# PRU_ICSSG1_PR1_MII_RT_PR1_SGMII0_CFG_SGMII0_local register map
Vendor: Texas Instruments
Peripheral module from a debugger description file (folder J7ES).
Registers are 32-bit, read-write, reset 0x0 unless marked. A register's access mark holds for its fields unless they carry their own. Offsets are as the file gives them; lines under a group give offsets from that group; [hi:lo] are bit positions; {n}, {i} and the like mark numbered series; 'fields as' and 'values as' point back to an identical list; <NAME> marks a mode.

## PRU_ICSSG1_PR1_MII_RT_PR1_SGMII0_CFG_SGMII0
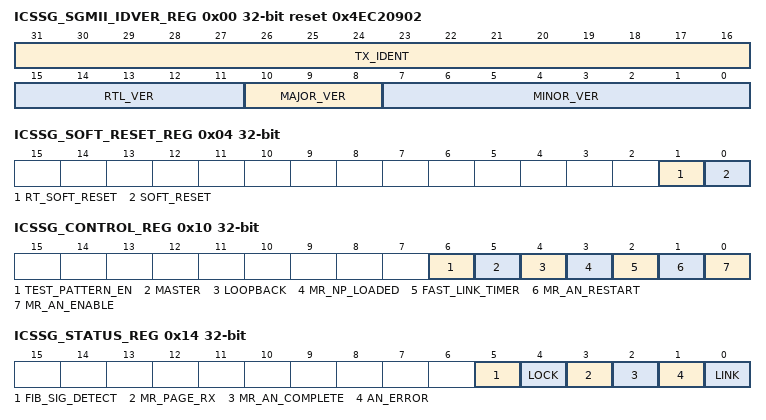
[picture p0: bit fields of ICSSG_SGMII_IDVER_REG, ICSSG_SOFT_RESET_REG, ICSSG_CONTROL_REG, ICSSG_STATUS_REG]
0x00 ICSSG_SGMII_IDVER_REG ro reset 0x4EC20902 — idver_reg
  [31:16] TX_IDENT
  [15:11] RTL_VER — RTL version value
  [10:8] MAJOR_VER — Major version value
  [7:0] MINOR_VER — Minor version value
0x04 ICSSG_SOFT_RESET_REG
  [1] RT_SOFT_RESET — Transmit and receive software reset
  [0] SOFT_RESET — Software reset
0x10 ICSSG_CONTROL_REG
  [6] TEST_PATTERN_EN — Test pattern enable
  [5] MASTER — Master mode
  [4] LOOPBACK — Loopback mode
  [3] MR_NP_LOADED — Next page loaded
  [2] FAST_LINK_TIMER
  [1] MR_AN_RESTART — Auto-negotiation restart
  [0] MR_AN_ENABLE — Auto-negotiation enable
0x14 ICSSG_STATUS_REG ro (reset mask 0xF)
  [5] FIB_SIG_DETECT — Fiber signal detect
  [4] LOCK
  [3] MR_PAGE_RX — Next page received
  [2] MR_AN_COMPLETE — Auto-negotiation complete
  [1] AN_ERROR — Auto-negotiation error
  [0] LINK — Link indicator
0x18 ICSSG_MR_ADV_ABILITY_REG
  [15:0] MR_ADV_ABILITY — Advertised ability
0x1C ICSSG_MR_NP_TX_REG
  [15:0] MR_NP_TX — Next page transmit
0x20 ICSSG_MR_LP_ADV_ABILITY_REG ro
  [15:0] MR_LP_ADV_ABILITY — Link partner advertised ability
0x24 ICSSG_MR_LP_NP_RX_REG ro
  [15:0] MR_LP_NP_RX — Link Partner Next Page Received
0x30 ICSSG_TX_CFG_REG
  [31:0] TX_CFG — Transmit configuration register output
0x34 ICSSG_RX_CFG_REG
  [31:0] RX_CFG — Receive configuration register output
0x38 ICSSG_AUX_CFG_REG
  [31:0] AUX_CFG — Auxiliary configuration register output
0x40 ICSSG_DIAG_CLEAR_REG
  [0] DIAG_CLEAR — Diagnostics clear
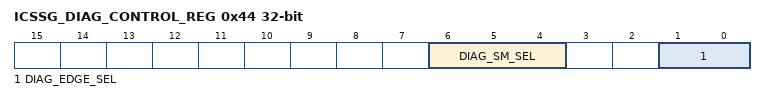
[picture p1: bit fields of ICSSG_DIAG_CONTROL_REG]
0x44 ICSSG_DIAG_CONTROL_REG
  [6:4] DIAG_SM_SEL — Diagnostic select
  [1:0] DIAG_EDGE_SEL — Diagnostics hold signals edge select
0x48 ICSSG_DIAG_STATUS_REG ro
  [15:0] DIAG_STATUS — Diagnostics status
